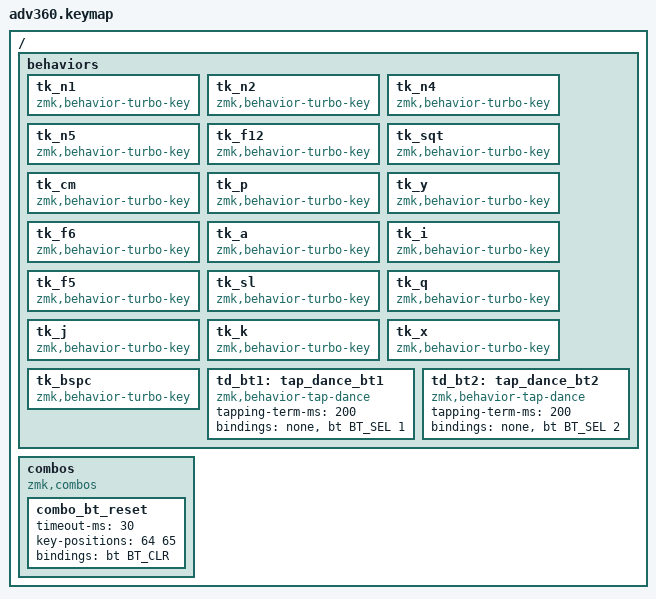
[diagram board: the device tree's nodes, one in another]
#include <dt-bindings/zmk/bt.h>

/*                                 ADVANTAGE 360 KEY MATRIX / LAYOUT MAPPING
 ╭────────────────────────────┬────────────────────────────╮ ╭────────────────────────────┬────────────────────────────╮
 │  0   1   2   3   4   5   6 │  7   8   9  10  11  12  13 │ │ LN5 LN4 LN3 LN2 LN1 LN0 -- │ --  RN0 RN1 RN2 RN3 RN4 RN5│
 │ 14  15  16  17  18  19  20 │ 21  22  23  24  25  26  27 │ │ LT5 LT4 LT3 LT2 LT1 LT0 -- │ --  RT0 RT1 RT2 RT3 RT4 RT5│
 │ 28  29  30  31  32  33  34 │ 39  40  41  42  43  44  45 │ │ LM5 LM4 LM3 LM2 LM1 LM0 -- │ --  RM0 RM1 RM2 RM3 RM4 RM5│
 │ 46  47  48  49  50  51 ╭───┴───╮ 54  55  56  57  58  59 │ │ LB5 LB4 LB3 LB2 LB1 LB0╭───┴───╮ RB0 RB1 RB2 RB3 RB4 RB5│
 │ 60  61  62  63  64╭────╯       ╰────╮71  72  73  74  75 │ │ --  --  --  --  --╭────╯       ╰────╮--  --  --  --  -- │
 ╰───────────────────┼────────┬────────┼───────────────────╯ ╰───────────────────┼────────┬────────┼───────────────────╯
                 ╭───╯ 35  36 │ 37  38 ╰───╮                                 ╭───╯ --  -- │ --  -- ╰───╮
                 │ 65  66  52 │ 53  69  70 │                                 │ LH1 LH0 -- │ --  RH0 RH1│
                 ╰───────╮ 67 │ 68 ╭───────╯                                 ╰───────╮ -- │ -- ╭───────╯
                         ╰────┴────╯                                                 ╰────┴────╯ */

#define KEYS_L LT0 LT1 LT2 LT3 LT4 LT5 LM0 LM1 LM2 LM3 LM4 LM5 LB0 LB1 LB2 LB3 LB4 LB5  // left hand
#define KEYS_R RT0 RT1 RT2 RT3 RT4 RT5 RM0 RM1 RM2 RM3 RM4 RM5 RB0 RB1 RB2 RB3 RB4 RB5 // right hand

#define LH0 65  // left thumb keys
#define LH1 66
#define RH0 69  // right thumb keys
#define RH1 70

#define LN0  5  // left-number row
#define LN1  4
#define LN2  3
#define LN3  2
#define LN4  1
#define LN5  0

#define RN0  8  // right-number row
#define RN1  9
#define RN2 10
#define RN3 11
#define RN4 12
#define RN5 13

#define LT0 19  // left-top row
#define LT1 18
#define LT2 17
#define LT3 16
#define LT4 15
#define LT5 14

#define RT0 22  // right-top row
#define RT1 23
#define RT2 24
#define RT3 25
#define RT4 26
#define RT5 27

#define LM0 33  // left-middle row
#define LM1 32
#define LM2 31
#define LM3 30
#define LM4 29
#define LM5 28

#define RM0 40  // right-middle row
#define RM1 41
#define RM2 42
#define RM3 43
#define RM4 44
#define RM5 45

#define LB0 51  // left-bottom row
#define LB1 50
#define LB2 49
#define LB3 48
#define LB4 47
#define LB5 46

#define RB0 54  // right-bottom row
#define RB1 55
#define RB2 56
#define RB3 57
#define RB4 58
#define RB5 59

/*                                 ADVANTAGE 360 KEY MATRIX / LAYOUT MAPPING
 ╭────────────────────────────┬────────────────────────────╮ ╭────────────────────────────┬────────────────────────────╮
 │  0   1   2   3   4   5   6 │  7   8   9  10  11  12  13 │ │ LN5 LN4 LN3 LN2 LN1 LN0 -- │ --  RN0 RN1 RN2 RN3 RN4 RN5│
 │ 14  15  16  17  18  19  20 │ 21  22  23  24  25  26  27 │ │ LT5 LT4 LT3 LT2 LT1 LT0 -- │ --  RT0 RT1 RT2 RT3 RT4 RT5│
 │ 28  29  30  31  32  33  34 │ 35  36  37  38  39  40  41 │ │ LM5 LM4 LM3 LM2 LM1 LM0 -- │ --  RM0 RM1 RM2 RM3 RM4 RM5│
 │ 42  43  44  45  46  47 ╭───┴───╮ 48  49  50  51  52  53 │ │ LB5 LB4 LB3 LB2 LB1 LB0╭───┴───╮ RB0 RB1 RB2 RB3 RB4 RB5│
 │ 54  55  56  57  58╭────╯       ╰────╮59  60  61  62  63 │ │ --  --  --  --  --╭────╯       ╰────╮--  --  --  --  -- │
 ╰───────────────────┼────────┬────────┼───────────────────╯ ╰───────────────────┼────────┬────────┼───────────────────╯
                 ╭───╯ 64  65 │ 66  67 ╰───╮                                 ╭───╯ --  -- │ --  -- ╰───╮
                 │ 68  69  70 │ 71  72  73 │                                 │ LH1 LH0 -- │ --  RH0 RH1│
                 ╰───────╮ 74 │ 75 ╭───────╯                                 ╰───────╮ -- │ -- ╭───────╯
                         ╰────┴────╯                                                 ╰────┴────╯ */


// #define X_LT    &kp GRAVE &kp N1 &kp N2 &kp N3 &kp N4 &kp N5 &kp F12     &kp F9 &kp N6 &kp N7 &kp N8 &kp N9 &kp N0 &none \
//                 &kp TAB

//               0     1      2      3      4      5      6          7            8      9      10     11     12     13
#define X_LT    &none &kp N1 &kp N2 &kp N3 &kp N4 &kp N5 &none        &kp C_VOL_UP &kp N6 &kp N7 &kp N8 &kp N9 &kp N0 &none \
                &kp TAB
//               14

//               20    21
#define X_MT    &none &kp C_VOL_DN
//               27
#define X_RT    &none

//               28
#define FN_LM  &kp HOME
//               28
#define X_LM    &kp ESCAPE

//               34    64           65       66       67     35
#define X_MM    &none &bt BT_SEL 0 &td_bt1 &td_bt2 &to 8 &mute_pp
//               41
#define X_RM    &kp RETURN

//               42
#define X_LB    &kp LSHFT
//               70            71
#define X_MB    &kp LG(LA(D)) &tog QWERTY
//               53
#define X_RB    &none

//               54    55    56    57    58
#define X_LH    &kp LCTRL &none &none &none &kp C_VOL_DN

//               74            75
#define X_MH    &game_toggle  SMART_NUM

//               59    60    61    62
#define X_RH    &none &none &none &none

/*
ZMK_LAYER(new,
//╭──────╮ ╭────────────╮ ╭──────╮ ╭─────────────╮ ╭──────╮
   X_LT                     X_MT                      X_RT
//├──────┤ ├────────────┤ ├──────┤ ├─────────────┤ ├──────┤
    X_LM                    X_MM                     X_RM
//├──────┤ ├────────────┤ ├──────┤ ├─────────────┤ ├──────┤
    X_LB                    X_MB                     X_RB
//├──────┤ ╰────────────┤ ├──────┤ ├─────────────╯ ├──────┤
    X_LH                   X_MH                      X_RH
//╰──────╯                ╰──────╯                 ╰──────╯
)                                               
*/


/ {
    behaviors {
        tk_n1: tk_n1 { compatible = "zmk,behavior-turbo-key"; #binding-cells = <1>; };
        tk_n2: tk_n2 { compatible = "zmk,behavior-turbo-key"; #binding-cells = <1>; };
        tk_n4: tk_n4 { compatible = "zmk,behavior-turbo-key"; #binding-cells = <1>; };
        tk_n5: tk_n5 { compatible = "zmk,behavior-turbo-key"; #binding-cells = <1>; };
        tk_f12: tk_f12 { compatible = "zmk,behavior-turbo-key"; #binding-cells = <1>; };
        tk_sqt: tk_sqt { compatible = "zmk,behavior-turbo-key"; #binding-cells = <1>; };
        tk_cm: tk_cm { compatible = "zmk,behavior-turbo-key"; #binding-cells = <1>; };
        tk_p: tk_p { compatible = "zmk,behavior-turbo-key"; #binding-cells = <1>; };
        tk_y: tk_y { compatible = "zmk,behavior-turbo-key"; #binding-cells = <1>; };
        tk_f6: tk_f6 { compatible = "zmk,behavior-turbo-key"; #binding-cells = <1>; };
        tk_a: tk_a { compatible = "zmk,behavior-turbo-key"; #binding-cells = <1>; };
        tk_i: tk_i { compatible = "zmk,behavior-turbo-key"; #binding-cells = <1>; };
        tk_f5: tk_f5 { compatible = "zmk,behavior-turbo-key"; #binding-cells = <1>; };
        tk_sl: tk_sl { compatible = "zmk,behavior-turbo-key"; #binding-cells = <1>; };
        tk_q: tk_q { compatible = "zmk,behavior-turbo-key"; #binding-cells = <1>; };
        tk_j: tk_j { compatible = "zmk,behavior-turbo-key"; #binding-cells = <1>; };
        tk_k: tk_k { compatible = "zmk,behavior-turbo-key"; #binding-cells = <1>; };
        tk_x: tk_x { compatible = "zmk,behavior-turbo-key"; #binding-cells = <1>; };
        tk_bspc: tk_bspc { compatible = "zmk,behavior-turbo-key"; #binding-cells = <1>; };

        td_bt1: tap_dance_bt1 {
            compatible = "zmk,behavior-tap-dance";
            #binding-cells = <0>;
            tapping-term-ms = <200>;
            bindings = <&none>, <&bt BT_SEL 1>;
        };

        td_bt2: tap_dance_bt2 {
            compatible = "zmk,behavior-tap-dance";
            #binding-cells = <0>;
            tapping-term-ms = <200>;
            bindings = <&none>, <&bt BT_SEL 2>;
        };
    };

    combos {
        compatible = "zmk,combos";
        combo_bt_reset {
            timeout-ms = <30>;
            key-positions = <64 65>;
            bindings = <&bt BT_CLR>;
        };
    };
};

#define CONFIG_WIRELESS 1

#define CUSTOM_WOW \
&kp GRAVE  &tk_n1 N1    &tk_n2 N2    &kp N3     &tk_n4 N4 &tk_n5 N5 &tk_f12 F12                                              &kp F9    &kp N6  &kp N7         &kp N8  &kp N9    &kp N0     ___ \
&kp TAB    &tk_sqt SQT  &tk_cm COMMA &kp PERIOD &tk_p P    &tk_y Y    &tk_f6 F6                                                                 &kp F10   &kp F   &kp G          &kp C   &kp R     &kp L      &kp SEMI \
&kp ESC    &tk_a A      &kp O        &kp E      &kp U      &tk_i I    &tk_f5 F5      ___   &kp LALT     ___  ___                      &kp F11   &kp D   &hmr LSHFT H   &hmr LCTRL T  &hmr LGUI N   &hmr LALT S      &kp ENTER \
&kp LSHFT  &tk_sl SLASH &tk_q Q      &tk_j J    &tk_k K    &tk_x X                         &kp DEL      &kp PRINTSCREEN                               &kp B   &kp M          &kp W   &kp V     &kp Z      ___  \
&kp LCTRL  &kp UP       &kp DOWN     &kp LBKT   &kp N9                &kp SPACE  &tk_bspc BSPC &to DEF  ___ ___ ___        ___  &none   ___ ___ ___  \

#define CUSTOM_GAME \
&kp GRAVE  &kp N1     &kp N2     &kp N3     &kp N4  &kp N5  &kp F12                                                                &kp F9    &kp N6  &kp N7         &kp N8  &kp N9    &kp N0     ___ \
&kp TAB    &kp SQT    &kp COMMA  &kp PERIOD &kp P   &kp Y   &kp F6                                                                 &kp F10   &kp F   &kp G          &kp C   &kp R     &kp L      &kp SEMI \
&kp ESC    &kp A      &kp O      &kp E      &kp U   &kp I   &kp F5     ___   &kp LALT     ___  ___                      &kp F11   &kp D   &kp H          &kp T   &kp N     &kp S      &kp ENTER \
&kp LSHFT  &kp SLASH  &kp Q      &kp J      &kp K   &kp X                    &kp DEL      &kp PRINTSCREEN                               &kp B   &kp M          &kp W   &kp V     &kp Z      ___  \
&kp LCTRL  &kp UP     &kp DOWN   &kp LBKT   &kp N9         &kp SPACE  &kp BSPC  &to DEF  ___ ___ ___        ___  &none   ___ ___ ___  \


/* source the main keymap */

/* activate bluetooth */
#define CONFIG_WIRELESS 1

/* leds and backlights */
#include <dt-bindings/zmk/rgb.h>
#include <dt-bindings/zmk/backlight.h>

/* source the main keymap */
#include "base.keymap"
